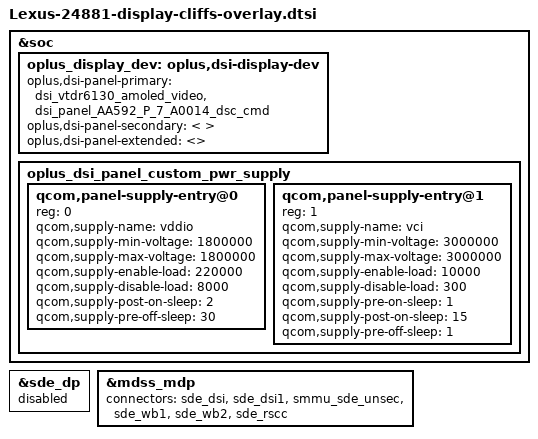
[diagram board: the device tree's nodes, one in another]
#include "panel/dsi-panel-AA592-P-7-A0014-dsc-cmd.dtsi"

&soc {
	oplus_display_dev: oplus,dsi-display-dev {
		oplus,dsi-panel-primary = <
			&dsi_vtdr6130_amoled_video
			&dsi_panel_AA592_P_7_A0014_dsc_cmd
		>;
		oplus,dsi-panel-secondary = <
		>;
		oplus,dsi-panel-extended = <>;
	};


	oplus_dsi_panel_custom_pwr_supply: oplus_dsi_panel_custom_pwr_supply {
		#address-cells = <1>;
		#size-cells = <0>;

		qcom,panel-supply-entry@0 {
			reg = <0>;
			qcom,supply-name = "vddio";
			qcom,supply-min-voltage = <1800000>;
			qcom,supply-max-voltage = <1800000>;
			qcom,supply-enable-load = <220000>;
			qcom,supply-disable-load = <8000>;
			qcom,supply-post-on-sleep = <2>;
			qcom,supply-pre-off-sleep = <30>;
		};

		qcom,panel-supply-entry@1 {
			reg = <1>;
			qcom,supply-name = "vci";
			qcom,supply-min-voltage = <3000000>;
			qcom,supply-max-voltage = <3000000>;
			qcom,supply-enable-load = <10000>;
			qcom,supply-disable-load = <300>;
			qcom,supply-pre-on-sleep = <1>;
			qcom,supply-post-on-sleep = <15>;
			qcom,supply-pre-off-sleep = <1>;
		};
	};
};

&sde_dp {
	status = "disabled";
};

&mdss_mdp {
	connectors = <&sde_dsi &sde_dsi1 &smmu_sde_unsec &sde_wb1 &sde_wb2 &sde_rscc>;
};
